# STM32MP25_CM33 register map
File version: 1.3
CPU: CM33 r0p1, little endian, MPU, FPU, vendor SysTick, 8 interrupt priority bits
Registers are 32-bit, read-write, reset 0x0 unless marked. A register's access mark holds for its fields unless they carry their own. Offsets are from the block's base; [hi:lo] are bit positions; lines under a group give offsets from that group; {n}, {i} and the like mark numbered series; 'fields as' and 'values as' point back to an identical list.

## HSEM — HSEM address block description
Base 0x46240000
Same registers: HSEM_S 0x56240000
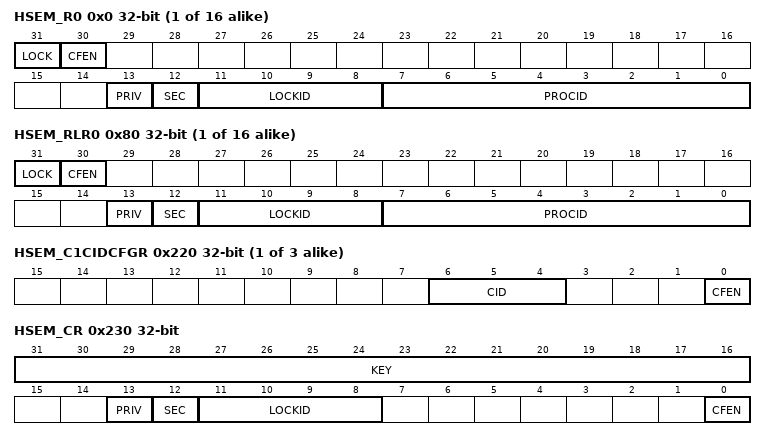
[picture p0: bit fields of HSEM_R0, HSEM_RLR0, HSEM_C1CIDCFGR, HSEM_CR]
{0x0+4i} HSEM_R{i} (i=0..15) — HSEM register semaphore {i}
  [31] LOCK — Lock indication This bit can be written and read by software.
    0=On write free semaphore (only when LOCKID and PROCID match), on read semaphore is free; 1=On write try to lock semaphore, on read semaphore is locked
  [30] CFEN ro — Semaphore CID filter indication This bit is updated, with the CID filtering information in HSEM_GpCIDCFGR.CFEN and HSEM_CnCIDCFGR.CFEN, by HW when semaphore is locked. This bit is set only when CID filtering is enabled for at least one CID in both HSEM_GpCIDCFGR.CFEN and HSEM_CnCIDCFGR.CFEN. Read only by software.
    0=Semaphore is not CID filtered, LOCKID field indicated MASTERID or semaphore is free; 1=Semaphore is CID filtered, LOCKID field indicates CID
  [13] PRIV — Semaphore privilege Written by software - When the semaphore is free and the LOCK bit is at the same time written to 1, and the LOCKID matches the AHB bus master ID or CID, SEC and PRIV matches the AHB bus master definition. - When the semaphore is unlocked (LOCK written to 0 and AHB bus master ID or CID matched LOCKID, SEC and PRIV matches the AHB bus master definition, the PRIV is cleared to 0. - When the semaphore is unlocked (LOCK bit written to 0 and AHB bus master ID or CID does not match LOCKID and/or SEC or PRIV do not match AHB bus master definition, the PRIV is not affected. - Write when LOCK bit is already 1 (semaphore locked), the PRIV is not affected. - An authorized read returns the stored PRIV value.
    0=Semaphore free or locked by unprivileged compartment; 1=Semaphore locked by privilege compartment
  [12] SEC — Semaphore secure Written by software - When the semaphore is free and the LOCK bit is at the same time written to 1, and the LOCKID matches the AHB bus master ID or CID, SEC and PRIV matches the AHB bus master definition. - When the semaphore is unlocked (LOCK written to 0 and AHB bus master ID or CID matched LOCKID, SEC and PRIV matches the AHB bus master definition, the SEC is cleared to 0. - When the semaphore is unlocked (LOCK bit written to 0 and AHB bus master ID or CID does not match LOCKID and/or SEC or PRIV do not match AHB bus master definition, the SEC is not affected. - Write when LOCK bit is already 1 (semaphore locked), the SEC is not affected. - An authorized read returns the stored SEC value.
    0=Semaphore free or locked by non-secure compartment; 1=Semaphore locked by secure compartment
  [11:8] LOCKID — Semaphore LOCKID Written by software - When the semaphore is free and the LOCK bit is at the same time written to 1 and the LOCKID matches the AHB bus master ID or CID, SEC and PRIV matches the AHB bus master protection. - When the semaphore is unlocked (LOCK written to 0 and AHB bus master ID or CID matched LOCKID, SEC and PRIV matches the AHB bus master protection, the LOCKID is cleared to 0. - When the semaphore is unlocked (LOCK bit written to 0 or AHB bus master ID or CID does not match LOCKID and/or SEC or PRIV do not match AHB bus master protection, the LOCKID is not affected. - Write when LOCK bit is already 1 (semaphore locked), the LOCKID is not affected. - An authorized read returns the stored LOCKID value.
  [7:0] PROCID — Semaphore PROCID Written by software -When the semaphore is free and the LOCK is written to 1, and the LOCKID matches the AHB bus master ID or CID, SEC and PRIV matches the AHB bus master definition, PROCID is set to the written data. - When the semaphore is unlocked, LOCK written to 0 and AHB bus master ID or CID matched LOCKID, SEC and PRIV matches the AHB bus master protection, the PROCID is cleared to 0. - When the semaphore is unlocked, LOCK bit written to 0 and AHB bus master ID or CID does not match LOCKID and/or SEC or PRIV do not match the AHB bus master definition, the PROCID is not affected. - Write when LOCK bit is already 1 (semaphore locked), the PROCID is not affected. - An authorized read returns the stored PROCID value.
{0x80+4i} HSEM_RLR{i} ro (i=0..15) — HSEM read lock register semaphore {i}
  [31] LOCK — Lock indication This bit is read only by software at this address. - When the semaphore is free: A read with a valid AHB bus master ID or CID and SEC and PRIV locks the semaphore and returns 1. - When the semaphore is locked: A read with a valid AHB bus master ID or CID and SEC and PRIV returns 1 (the LOCKID and SEC and PRIV and PROCID reflect the already locked semaphore information).
  [30] CFEN — Semaphore CID filter indication This bit is updated by hardware when semaphore is locked with the CID filtering information in HSEM_GpCIDCFGR.CFEN and HSEM_CnCIDCFGR.CFEN. This bit is set only when CID filtering is enabled for at least one CID in both HSEM_GpCIDCFGR.CFEN and HSEM_CnCIDCFGR.CFEN.
    0=Semaphore is free or locked and not CID filtered, LOCKID field indicates AHB bus master ID; 1=Semaphore is locked and CID filtered, LOCKID field indicated AHB bus master CID
  [13] PRIV — Semaphore privilege This field is read only by software at this address. - When the semaphore is free: A read with a valid AHB bus master ID or CID and SEC and PRIV locks the semaphore and hardware sets the PRIV to the valid AHB bus master privileged definition. - When the semaphore is locked: A read with a valid AHB bus master ID or CID and SEC and PRIV returns the PRIV of the AHB bus master that has locked the semaphore.
    0=Semaphore free or locked by unprivileged compartment; 1=Semaphore locked by privileged compartment
  [12] SEC — Semaphore secure. This field is read only by software at this address. - When the semaphore is free: A read with a valid AHB bus master ID or CID and SEC and PRIV locks the semaphore and hardware sets the SEC to the valid AHB bus master security definition. - When the semaphore is locked: A read with a valid AHB bus master ID or CID and SEC and PRIV returns the SEC of the AHB bus master that has locked the semaphore.
    values as HSEM_R0.SEC
  [11:8] LOCKID — Semaphore LOCKID This field is read only by software at this address. On a read, when the semaphore is free, the hardware sets the LOCKID to the AHB bus master ID reading the semaphore. The LOCKID of the AHB bus master locking the semaphore is read. On a read when the semaphore is locked, this field returns the LOCKID of the AHB bus master that has locked the semaphore.
  [7:0] PROCID — Semaphore processor ID This field is read only by software at this address. - On a read when the semaphore is free: A read with a valid AHB bus master ID or CID and SEC and PRIV locks the semaphore and hardware sets the PROCID to 0. - When the semaphore is locked: A read with a valid AHB bus master ID or CID and SEC and PRIV returns the PROCID of the AHB bus master that has locked the semaphore.
{0xF0+0x10*i} HSEM_C{i}IER (i=1..3) — HSEM non-secure interrupt enable register
  [15:0] ISE — Non-secure Interrupt(n) semaphore x enable bit This bit is read and written by software. When semaphore x SECx is disabled, bit x can be accessed with secure and non-secure access. When semaphore x SECx is enabled, bit x is forced to 0 and cannot be accessed, write to this bit is discarded and a read returns 0. When semaphore x PRIVx is disabled, bit x can be accessed with privilege and unprivileged access. When semaphore x PRIVx is enabled, bit x can be accessed only with privileged access. Unprivileged write to this bit is discarded, unprivileged read returns 0. When semaphore x CID white list is disabled by HSEM_GpCIDCFGR.CFEN, bit x can be accessed according the register global access definition shown above. When semaphore x CID white list is enabled by HSEM_GpCIDCFGR.CFEN, bit x can only be accessed by the processor(s) as defined in the HSEM_CnCIDCFGR when the processor CID is part of the HSEM_GpCIDCFGR CID white list. When its CID is not in the white list bit x is reset to zero and can’t be accessed, writing to this bit is discarded and read return 0 value.
    0=Non-secure Interrupt(n) generation for semaphore x disabled (masked); 1=Non-secure Interrupt(n) generation for semaphore x enabled (not masked)
{0xF4+0x10*i} HSEM_C{i}ICR (i=1..3) — HSEM non-secure interrupt clear register
  [15:0] ISC — Non-secure Interrupt(n) semaphore x clear bit This bit is written by software, and is always read 0. When semaphore x SECx is disabled, bit x can be accessed with secure and non-secure access. When semaphore x SECx is enabled, bit x cannot be accessed, write to this bit is discarded. When semaphore x PRIVx is disabled, bit x can be accessed with privileged and unprivileged access. When semaphore x PRIVx is enabled, bit x can only be accessed with privileged access. Unprivileged write to this bit is discarded. When semaphore x CID white list is disabled by HSEM_GpCIDCFGR.CFEN, bit x can be accessed according to the register global access definition shown above. When semaphore x CID white list is enabled by HSEM_GpCIDCFGR.CFEN, bit x can be accessed only by the processor(s) as defined in the HSEM_CnCIDCFGR when the processor CID is part of the HSEM_GpCIDCFGR CID white list. When its CID is not in the white list bit x is reset to 0 and cannot be accessed, writing to this bit is discarded and read returns 0.
    0=non-secure Interrupt(n) semaphore x status ISFx and masked status MISFx not affected; 1=non-secure Interrupt(n) semaphore x status ISFx and masked status MISFx cleared
{0xF8+0x10*i} HSEM_C{i}ISR ro (i=1..3) — HSEM non-secure interrupt status register
  [15:0] ISF — Interrupt semaphore x status bit before enable (mask) This bit is set by hardware, and reset only by software. This bit is cleared by software writing the corresponding HSEM_CnICR bit.
    0=Interrupt semaphore x status, no interrupt pending; 1=Interrupt semaphore x status, interrupt pending
{0xFC+0x10*i} HSEM_C{i}MISR ro (i=1..3) — HSEM non-secure interrupt status register
  [15:0] MISF — Masked non-secure interrupt(n) semaphore x status bit after enable (mask) This bit is set by hardware and read only by software. This bit is cleared by software writing the corresponding HSEM_CnICR bit. This bit is read as 0 when semaphore x status is masked in HSEM_CnIER bit x. When semaphore x SECx is disabled, bit x can be accessed with secure and non-secure access. When semaphore x SECx is enabled, bit x cannot be accessed, read returns 0. When semaphore x PRIVx is disabled, bit x can be accessed with privileged and unprivileged access. When semaphore x PRIVx is enabled, bit x can be accessed only with privileged access. Unprivileged read returns 0. When semaphore x CID white list is disabled by HSEM_GpCIDCFGR.CFEN, bit x can be accessed according the register global access definition shown above. When semaphore x CID white list is enabled by HSEM_GpCIDCFGR.CFEN, bit x can be accessed only by the processor(s) as defined in the HSEM_CnCIDCFGR when the processor CID is part of the HSEM_GpCIDCFGR CID white list. When its CID is not in the white list bit x is reset to 0 and cannot be accessed, read returns 0.
    0=non-secure interrupt(n) semaphore x status after masking not pending; 1=non-secure interrupt(n) semaphore x status after masking pending
{0x170+0x10*i} HSEM_SC{i}IER (i=1..3) — HSEM secure interrupt enable register
  [15:0] SISE — Secure interrupt(n) semaphore x enable bit This bit is read and written by software. When semaphore x PRIVx is disabled, bit x can be accessed with secure privilege and secure unprivileged access. When semaphore x PRIVx is enabled, bit x can be accessed only with secure privilege access. secure unprivileged write to this bit is discarded, secure unprivileged read return 0 value. When semaphore x CID white list is disabled by HSEM_GpCIDCFGR.CFEN, bit x can be accessed according the register global access definition shown above. When semaphore x CID white list is enabled by HSEM_GpCIDCFGR.CFEN, bit x can be accessed only by the secure processor(s) as defined in the HSEM_CnCIDCFGR when the processor CID is part of the HSEM_GpCIDCFGR CID white list. When its CID is not in the white list bit x is reset to 0 and cannot be accessed, writing to this bit is discarded and read returns 0.
    0=Secure interrupt(n) generation for semaphore x is disabled (masked); 1=Secure interrupt(n) generation for semaphore x is enabled (not masked)
{0x174+0x10*i} HSEM_SC{i}ICR (i=1..3) — HSEM secure interrupt clear register
  [15:0] SISC — Secure interrupt(n) semaphore x clear bit This bit is written by software, and is always read 0. When semaphore x PRIVx is disabled, bit x can be accessed with secure privilege and secure unprivileged access. When semaphore x PRIVx is enabled, bit x can be accessed only with secure privilege access. Secure unprivileged write to this bit is discarded. When semaphore x CID white list is disabled by HSEM_GpCIDCFGR.CFEN, bit x can be accessed according the register global access definition shown above. When semaphore x CID white list is enabled by HSEM_GpCIDCFGR.CFEN, bit x can be accessed only by the secure processor(s) as defined in the HSEM_CnCIDCFGR when the processor CID is part of the HSEM_GpCIDCFGR CID white list. When its CID is not in the white list bit x is reset to 0 and cannot be accessed, writing to this bit is discarded and read returns 0.
    0=Secure interrupt(n) semaphore x status ISFx and masked status MISFx not affected; 1=Secure interrupt(n) semaphore x status ISFx and masked status MISFx cleared
{0x178+0x10*i} HSEM_SC{i}ISR ro (i=1..3) — HSEM secure interrupt status register
  [15:0] SISF — Secure interrupt(n) semaphore x status bit before enable (mask) This bit is set by hardware and read only by software. Bit is cleared by software writing the corresponding HSEM_SCnICR bit x. When semaphore x PRIVx is disabled, bit x can be accessed with secure privilege and secure unprivileged access. When semaphore x PRIVx is enabled, bit x can be accessed only with secure privilege access. Secure unprivileged read return 0 value. When semaphore x CID white list is disabled by HSEM_GpCIDCFGR.CFEN, bit x can be accessed according the register global access definition shown above. When semaphore x CID white list is enabled by HSEM_GpCIDCFGR.CFEN, bit x can be accessed only by the secure processor(s) as defined in the HSEM_CnCIDCFGR when the processor CID is part of the HSEM_GpCIDCFGR CID white list. When its CID is not in the white list bit x is reset to 0 and cannot be accessed, read return 0 value.
    0=Secure interrupt(n) semaphore x status, no interrupt pending; 1=Secure interrupt(n) semaphore x status, interrupt pending
{0x17C+0x10*i} HSEM_SC{i}MISR ro (i=1..3) — HSEM secure masked interrupt status register
  [15:0] SMISF — Secure masked interrupt(n) semaphore x status bit after enable (mask) This bit is set by hardware and read only by software. Bit is cleared by software writing the corresponding HSEM_SCnICR bit x. Bit is read as 0 when semaphore x status is masked in HSEM_SCnIER bit x. When semaphore x PRIVx is disabled, bit x can be accessed with secure privilege and secure unprivileged access. When semaphore x PRIVx is enabled, bit x can be accessed only with secure privilege access. Secure unprivileged read return 0 value. When semaphore x CID white list is disabled by HSEM_GpCIDCFGR.CFEN, bit x can be accessed according the register global access definition shown above. When semaphore x CID white list is enabled by HSEM_GpCIDCFGR.CFEN, bit x can be accessed only by the secure processor(s) as defined in the HSEM_CnCIDCFGR when the processor CID is part of the HSEM_GpCIDCFGR CID white list. When its CID is not in the white list bit x is reset to 0 and cannot be accessed, read return 0 value.
    0=Secure interrupt(n) semaphore x status after masking not pending; 1=Secure interrupt(n) semaphore x status after masking pending
0x200 HSEM_SECCFGR — HSEM security configuration register
  [15:0] SEC — Semaphore x security attribute This bit is set and cleared by software. When semaphore x CID white list is disabled by HSEM_GpCIDCFGR.CFEN, bit x can be written by any secure processor. When semaphore x CID white list is enabled by HSEM_GpCIDCFGR.CFEN, bit x can only be written by secure processor CIDs, which are part of the CID white list. All CIDs have read accesses to the register bit x value.
    0=Semaphore x non-security, can be accessed by both secure and non-secure processors. When unlocking semaphore x both a secure and non-secure interrupt can be generated.; 1=Semaphore x security, can be accessed only by secure processors. When unlocking semaphore x only a secure interrupt can be generated.
0x210 HSEM_PRIVCFGR — HSEM privilege configuration register
  [15:0] PRIV — Semaphore x privilege attribute This bit is set and cleared by software. When semaphore x SECx is disabled, bit x can be write accessed with secure privileged and non-secure privileged access. When semaphore x SECx is enabled, bit x can only be write accessed with secure privilege access. Non-secure privileged write access is discarded. Both secure and non-secure read return the register bit x value When semaphore x CID white list is disabled by HSEM_GpCIDCFGR.CFEN, bit x can be written by any privilege processor. When semaphore x CID white list is enabled by HSEM_GpCIDCFGR.CFEN, bit x can only be written by privileged processor CIDs, which are part of the CID white list. All CIDs have read accesses to the register bit x value.
    0=Semaphore x unprivileged, can be accessed by both privileged and unprivileged processors; 1=Semaphore x privileged, can be accessed only by privileged processors
{0x21C+4i} HSEM_C{i}CIDCFGR (i=1..3) — HSEM processor {i} CID configuration register
  [6:4] CID — processor[n] CID domain identification If CFEN = 0 these bits are ignored and there is no processor[n] CID filtering. Else: processor[n] CID domain identification number.
  [0] CFEN — processor[n] CID filtering enabled for HSEM_(S)CnIER, HSEM_(S)CnICR, HSEM_(S)CnISR, and HSEM_(S)CnMISR registers and for white list filter usage in HSEM_GpCIDCFGR.SEM_WLIST_Cn
    0=disable the CID filtering for processor[n]; 1=enable the CID filtering for processor[n]
0x230 HSEM_CR wo — HSEM clear register
  [31:16] KEY — Semaphore clear key This field can be written by software and is always read 0. If this key value does not match HSEM_KEYR.KEY, semaphores are not affected. If this key value matches HSEM_KEYR.KEY, all semaphores matching the LOCKID are cleared to the free state.
  [13] PRIV — PRIV value of semaphores to be cleared. This field can be written by software, is always read 0. Indicates the PRIV for which the semaphores are cleared when writing the HSEM_CR.
  [12] SEC — SEC value of semaphores to be cleared. This field can be written by software, is always read 0. Indicates the SEC for which the semaphores are cleared when writing the HSEM_CR
  [11:8] LOCKID — LOCKID of semaphores to be cleared This field can be written by software and is always read 0. This field indicates the LOCKID for which the semaphores are cleared when writing the HSEM_CR.
  [0] CFEN — Semaphore CID filtered. This field can be written by software, is always read 0.
    0=Semaphore not CID filtered, LOCKID field represents MASTERID; 1=Semaphore CID filtered, LOCKID field represents CID
0x234 HSEM_KEYR — HSEM clear semaphore key register
  [31:16] KEY — Semaphore clear key This field can be written and read by software. Key value to match when clearing semaphores.
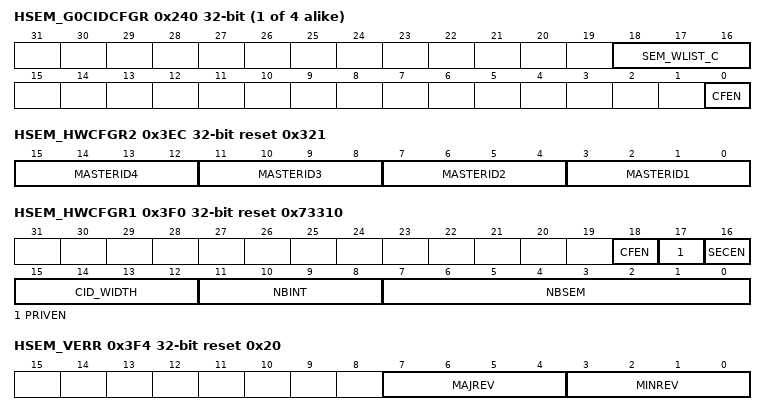
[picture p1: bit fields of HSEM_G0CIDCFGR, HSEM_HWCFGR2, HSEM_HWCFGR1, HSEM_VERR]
{0x240+4i} HSEM_G{i}CIDCFGR (i=0..3) — HSEM CID configuration register
  [18:16] SEM_WLIST_C — Semaphore group p CID filtering enable for processor n CID (n = 1 to 3). This bit is set and cleared by software. If CID filtering is disabled in HSEM_GpCIDCFGR.CFEN, these bits are ignored, else: If CID filtering is disabled in HSEM_CnCIDCFGR.CFEN, bit n is ignored, (n = 1 to 3) and HSEM_CnCIDCFGR.CID is black listed, else:
    0=Processor n CID as defined in HSEM_CnCIDCFGR.CID is black listed for Semaphore group p; 1=Processor n CID as defined in HSEM_CnCIDCFGR.CID is white listed for Semaphore group p
  [0] CFEN — Semaphore group p global CID filtering enable. This bit is set and cleared by software.
    0=Semaphore group p CID filtering disabled. (Group p semaphores can be accessed by all authorized MASTERIDs); 1=Semaphore group p CID filtering enabled. (Group p semaphores can only be accessed by white listed CIDs)
0x3EC HSEM_HWCFGR2 ro reset 0x321 — HSEM hardware configuration register 2
  [4n-1:4n-4] MASTERID{n} (n=1..4) — Hardware configuration valid bus masters ID{n}
0x3F0 HSEM_HWCFGR1 ro reset 0x73310 — HSEM hardware configuration register 1
  [18] CFEN — Hardware configuration compartment filtering enable
  [17] PRIVEN — Hardware configuration privilege protection enable
  [16] SECEN — Hardware configuration security protection enable
  [15:12] CID_WIDTH — Hardware configuration compartment isolation bus width
  [11:8] NBINT — Hardware configuration number of interrupts/supported number of master ID.
  [7:0] NBSEM — Hardware configuration number of semaphores
0x3F4 HSEM_VERR ro reset 0x20 — HSEM version register
  [7:4] MAJREV — HSEM major revision number
  [3:0] MINREV — HSEM minor revision number
0x3F8 HSEM_IPIDR ro reset 0x100072 — HSEM identification register
  [31:0] IPID — HSEM identifier
0x3FC HSEM_SIDR ro reset 0xA3C5DD01 — HSEM size identification register
  [31:0] SID — HSEM size
